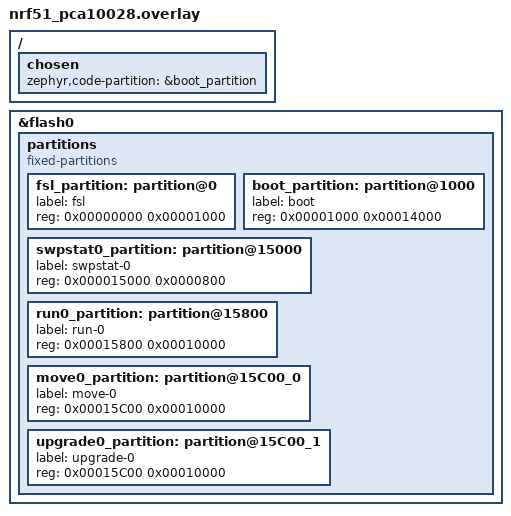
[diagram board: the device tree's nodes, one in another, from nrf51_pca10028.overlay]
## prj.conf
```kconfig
#CONFIG_HAS_FLASH_LOAD_OFFSET=y
CONFIG_USE_DT_CODE_PARTITION=y
CONFIG_TEXT_SECTION_OFFSET=0x200
CONFIG_ZB_EIGHT=y
CONFIG_ZB_EIGHT_DFU_BLOCK_BUF_SIZE=512
CONFIG_ZB_EIGHT_FSL_SUPPORT=y

CONFIG_ARM_MPU=n

CONFIG_MAIN_STACK_SIZE=320
CONFIG_IDLE_STACK_SIZE=128

CONFIG_LOG=n
CONFIG_CONSOLE=n
CONFIG_EARLY_CONSOLE=n
CONFIG_UART_CONSOLE=n
CONFIG_STDOUT_CONSOLE=n
CONFIG_PRINTK=n
CONFIG_SERIAL=n
CONFIG_GPIO=n
CONFIG_I2C=n
CONFIG_WATCHDOG=n
CONFIG_PINMUX=n
CONFIG_SPI=n
CONFIG_SYS_POWER_MANAGEMENT=n

#CONFIG_BT=y
#CONFIG_BT_SMP=n
#CONFIG_BT_PERIPHERAL=y
#CONFIG_BT_GATT_CACHING=n
#CONFIG_BT_DEBUG_LOG=n
#CONFIG_BT_GATT_DIS=n
#CONFIG_BT_GATT_DIS_PNP=n
#CONFIG_BT_DEVICE_NAME="Zephyr"
#CONFIG_BT_DEVICE_APPEARANCE=833

CONFIG_BT=y
CONFIG_BT_SMP=n
CONFIG_BT_PERIPHERAL=y
CONFIG_BT_GATT_CACHING=n
CONFIG_BT_CTLR_PRIVACY=n
CONFIG_BT_PHY_UPDATE=n
CONFIG_BT_DATA_LEN_UPDATE=n
#CONFIG_BT_ASSERT=n
CONFIG_BT_CTLR_LE_ENC=n
CONFIG_BT_CTLR_CONN_PARAM_REQ=n
CONFIG_BT_CTLR_EXT_REJ_IND=n
CONFIG_BT_CTLR_SLAVE_FEAT_REQ=n
CONFIG_BT_CTLR_MIN_USED_CHAN=n
CONFIG_BT_CTLR_CHAN_SEL_2=n
CONFIG_BT_CTLR_ADV_EXT=n
CONFIG_BT_CTLR_DTM_HCI=n
CONFIG_BT_CTLR_ADVANCED_FEATURES=n
```

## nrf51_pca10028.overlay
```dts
/*
 * Copyright (c) 2019 Laczen
 *
 * SPDX-License-Identifier: Apache-2.0
 */

/delete-node/ &boot_partition;
/delete-node/ &scratch_partition;
/delete-node/ &slot0_partition;
/delete-node/ &slot1_partition;
/delete-node/ &storage_partition;
/ {
	chosen {
		zephyr,code-partition = &boot_partition;
	};
};

&flash0 {
	/*
	 * For more information, see:
	 * http://docs.zephyrproject.org/latest/guides/dts/index.html#flash-partitions
	 */
	partitions {
		compatible = "fixed-partitions";
		#address-cells = <1>;
		#size-cells = <1>;

		fsl_partition: partition@0 {
			label = "fsl";
			reg = <0x00000000 0x00001000>;
		};
		boot_partition: partition@1000 {
			label = "boot";
			reg = <0x00001000 0x00014000>;
		};
		swpstat0_partition: partition@15000 {
			label = "swpstat-0";
			reg = <0x000015000 0x0000800>;
		};
		run0_partition: partition@15800 {
			label = "run-0";
			reg = <0x00015800 0x00010000>;
		};
		move0_partition: partition@15C00_0 {
			label = "move-0";
			reg = <0x00015C00 0x00010000>;
		};
		upgrade0_partition: partition@15C00_1 {
			label = "upgrade-0";
			reg = <0x00015C00 0x00010000>;
		};
	};
};
```

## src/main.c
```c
/* main.c - Application main entry point */

/*
 * Copyright (c) 2015-2016 Intel Corporation
 *
 * SPDX-License-Identifier: Apache-2.0
 */

#include <zephyr.h>

#include <bluetooth/gatt.h>

#include <zepboot/zb_fsl.h>
#include <zepboot/zb_dfu.h>
#include "nrf_dfu.h"


#include <logging/log.h>
LOG_MODULE_REGISTER(main);

struct bt_conn *default_conn;

static const struct bt_data ad[] = {
	BT_DATA_BYTES(BT_DATA_FLAGS, (BT_LE_AD_GENERAL | BT_LE_AD_NO_BREDR)),
	BT_DATA_BYTES(BT_DATA_UUID16_ALL, 0x0d, 0x18, 0x0f, 0x18, 0x05, 0x18),
};

static void connected(struct bt_conn *conn, u8_t err)
{
	if (err) {
		LOG_DBG("Connection failed (err 0x%02x)", err);
	} else {
		default_conn = bt_conn_ref(conn);
		LOG_INF("Connected");
	}
}

static void disconnected(struct bt_conn *conn, u8_t reason)
{
	LOG_INF("Disconnected (reason 0x%02x)", reason);

	if (default_conn) {
		bt_conn_unref(default_conn);
		default_conn = NULL;
	}
}

static struct bt_conn_cb conn_callbacks = {
	.connected = connected,
	.disconnected = disconnected,
};

static void bt_ready(int err)
{
	if (err) {
		LOG_DBG("Bluetooth init failed (err %d)", err);
		return;
	}

	LOG_INF("Bluetooth initialized");

	err = bt_le_adv_start(BT_LE_ADV_CONN_NAME, ad, ARRAY_SIZE(ad), NULL, 0);
	if (err) {
		LOG_DBG("Advertising failed to start (err %d)", err);
		return;
	}

	LOG_INF("Advertising successfully started");
}

static void reset_to_app(void)
{
	u8_t sm_idx;
	struct zb_fsl_ctx ctxb;

	zb_dfu_receive_flush(&sm_idx);
	LOG_INF("Receive finished, restarting to bootloader");
	/* Restart the bootloader */
	ctxb.addr = DT_FLASH_AREA_BOOT_OFFSET;
	ctxb.fl_dev = device_get_binding(DT_FLASH_AREA_BOOT_DEV);
	zb_fsl_verify(&ctxb);
	zb_fsl_boot(&ctxb);


}

struct nrf_dfu_cb dfu_callbacks = {
	.receive = &zb_dfu_receive,
	.reset_to_app = &reset_to_app,

};

static void dfu_init(void)
{
	nrf_dfu_init(&dfu_callbacks, 0U, 0U);
}

void main(void)
{
	int err;

	err = bt_enable(bt_ready);
	if (err) {
		LOG_DBG("Bluetooth init failed (err %d)", err);
		return;
	}

	bt_conn_cb_register(&conn_callbacks);
	dfu_init();
	LOG_INF("Welcome to ZEPBOOT bledfu uploader\n");

	while (1) {
		k_sleep(MSEC_PER_SEC);
	}
}
```

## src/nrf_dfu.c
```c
/** @file
 *  @brief NRF BLE DFU Service (Legacy)
 */

/*
 * Copyright (c) 2019 Linaro Limited
 *
 * SPDX-License-Identifier: Apache-2.0
 */

#include <zephyr.h>

#include <zephyr/types.h>
#include <misc/byteorder.h>

#include <bluetooth/bluetooth.h>
#include <bluetooth/conn.h>
#include <bluetooth/uuid.h>
#include <bluetooth/gatt.h>

#include <logging/log.h>
LOG_MODULE_REGISTER(nrf_dfu);

#include "nrf_dfu.h"

/* References:
 * https://infocenter.nordicsemi.com/topic/com.nordic.infocenter.sdk51.v10.0.0/bledfu_transport_bleservice.html
 * https://developer.nordicsemi.com/nRF51_SDK/nRF51_SDK_v5.x.x/doc/5.2.0/html/a00029.html
 */

#define DFU_OP_RFU		0
#define DFU_OP_START		1
#define DFU_OP_INIT		2
#define DFU_OP_RECV_IMG		3
#define DFU_OP_VALIDATE_IMG	4
#define DFU_OP_ACTIVATE_IMG	5
#define DFU_OP_RESET_SYS	6
#define DFU_OP_IMG_SIZE		7
#define DFU_OP_PKT_NOTIF_REQ	8
#define DFU_OP_RSP_CODE		16
#define DFU_OP_PKT_NOTIF	17

enum {
	RSP_RFU,
	RSP_SUCCESS,
	RSP_INVSTATE,
	RSP_NOTSUP,
	RSP_DATA_SIZE,
	RSP_CRC_ERROR,
	RSP_OP_FAILED
};

enum {
	DFU_STATE_NONE,
	DFU_STATE_BOOTLOADER,
	DFU_STATE_WAIT_START_PKT,
	DFU_STATE_STARTED,
	DFU_STATE_WAIT_INIT_PKT, /* Optional */
	DFU_STATE_RECV,
	DFU_STATE_RECV_DONE,
	DFU_STATE_VALIDATE,
};

struct dfu_start_data {
	u32_t softdevice_len;
	u32_t bootloader_len;
	u32_t application_len;
} __attribute__((packed));

struct dfu_init_data {
	u16_t device_type;
	u16_t device_revision;
	u32_t application_version;
	u16_t softdevice_id_count;
	u16_t softdevice_id[0];
} __attribute__((packed));

static struct bt_uuid_128 nrf_dfu_uuid = BT_UUID_INIT_128(
	0x23, 0xD1, 0xBC, 0xEA, 0x5F, 0x78, 0x23, 0x15,
	0xDE, 0xEF, 0x12, 0x12, 0x30, 0x15, 0x00, 0x00
);

static struct bt_uuid_128 nrf_dfu_control = BT_UUID_INIT_128(
	0x23, 0xD1, 0xBC, 0xEA, 0x5F, 0x78, 0x23, 0x15,
	0xDE, 0xEF, 0x12, 0x12, 0x31, 0x15, 0x00, 0x00
);

static struct bt_uuid_128 nrf_dfu_packet = BT_UUID_INIT_128(
	0x23, 0xD1, 0xBC, 0xEA, 0x5F, 0x78, 0x23, 0x15,
	0xDE, 0xEF, 0x12, 0x12, 0x32, 0x15, 0x00, 0x00
);

static struct bt_uuid_128 nrf_dfu_version = BT_UUID_INIT_128(
	0x23, 0xD1, 0xBC, 0xEA, 0x5F, 0x78, 0x23, 0x15,
	0xDE, 0xEF, 0x12, 0x12, 0x34, 0x15, 0x00, 0x00
);

static int state = DFU_STATE_NONE;
const struct bt_gatt_service_static nrf_dfu_svc;
static unsigned int exp_size, img_offset;
static u16_t device_type, device_revision;
static u16_t pkt_notif, pkt_count;
static u32_t crc16 = -1;
static struct nrf_dfu_cb *cb;

static void reset_state(struct bt_conn *conn)
{
	state = DFU_STATE_NONE;
	if (conn) {
		bt_conn_disconnect(conn, 0);
	}
}

static ssize_t write_control(struct bt_conn *conn,
			     const struct bt_gatt_attr *attr,
			     const void *buf, u16_t len, u16_t offset,
			     u8_t flags)
{
	u8_t opcode = ((u8_t *)buf)[0];
	u8_t rsp[3];

	/* prepare notification response */
	rsp[0] = DFU_OP_RSP_CODE;
	rsp[1] = opcode;
	rsp[2] = RSP_INVSTATE;

	switch (opcode) {
	case DFU_OP_START:
	{
		int err = 0;

		if (len != 2) {
			rsp[2] = RSP_OP_FAILED;
			bt_gatt_notify(conn, attr, &rsp, sizeof(rsp));
			break;
		}

		if (cb && cb->start) {
			err = cb->start(((u8_t *)buf)[1]);
		}

		if (state != DFU_STATE_BOOTLOADER
		    && cb && cb->reset_to_boot && !err) {
			/* Switch to bootloader mode */
			bt_conn_disconnect(conn, 0);
			state = DFU_STATE_BOOTLOADER;
			cb->reset_to_boot();
			break;
		}

		if (err) {
			rsp[2] = RSP_OP_FAILED;
			bt_gatt_notify(conn, attr, &rsp, sizeof(rsp));
			reset_state(conn);
		} else {
			pkt_notif = pkt_count = exp_size = img_offset = 0;
			state = DFU_STATE_WAIT_START_PKT;
		}

		break;
	}
	case DFU_OP_INIT:
	{
		if (state != DFU_STATE_STARTED) {
			bt_gatt_notify(conn, attr, &rsp, sizeof(rsp));
			reset_state(conn);
		} else {
			state = DFU_STATE_WAIT_INIT_PKT;
		}

		break;
	}
	case DFU_OP_RECV_IMG:
	{
		if (state != DFU_STATE_STARTED) {
			bt_gatt_notify(conn, attr, &rsp, sizeof(rsp));
			reset_state(conn);
		} else {
			state = DFU_STATE_RECV;
		}

		break;
	}
	case DFU_OP_VALIDATE_IMG:
	{
		if (state != DFU_STATE_RECV_DONE) {
			reset_state(conn);
		} else if (cb && cb->validate && cb->validate(crc16)) {
			rsp[2] = RSP_CRC_ERROR;
		} else {
			state = DFU_STATE_VALIDATE;
			rsp[2] = RSP_SUCCESS;
		}

		bt_gatt_notify(conn, attr, &rsp, sizeof(rsp));

		if (rsp[2] != RSP_SUCCESS) {
			reset_state(conn);
		}

		break;
	}
	case DFU_OP_ACTIVATE_IMG:
	{
		if (state != DFU_STATE_VALIDATE) {
			bt_gatt_notify(conn, attr, &rsp, sizeof(rsp));
			reset_state(conn);
		} else {
			reset_state(conn);

			if (cb && cb->reset_to_app) {
				/* Boot to app */
				cb->reset_to_app();
			}
		}
		break;
	}
	case DFU_OP_PKT_NOTIF_REQ:
	{
		/* pkt notification request */
		if (len != 3) {
			break;
		}

		pkt_notif = sys_le16_to_cpu(*(u16_t *)((u8_t *)buf + 1));

		break;
	}
	default: /* Unknown OPCODE */
		bt_gatt_notify(conn, attr, &rsp, sizeof(rsp));
	}

	return len;
}

static ssize_t write_packet(struct bt_conn *conn,
			    const struct bt_gatt_attr *attr,
			    const void *buf, u16_t len, u16_t offset,
			    u8_t flags)
{
	switch (state) {
	case DFU_STATE_WAIT_START_PKT:
	{
		u8_t rsp[] = {DFU_OP_RSP_CODE, DFU_OP_START, RSP_SUCCESS};
		const struct dfu_start_data *data = buf;

		if (len != sizeof(struct dfu_start_data)) {
			rsp[2] = RSP_OP_FAILED;
		} else {
			state = DFU_STATE_STARTED;
		}

		/* Only support Application update */
		exp_size = sys_le32_to_cpu(data->application_len);
		img_offset = 0;

		bt_gatt_notify(conn,  &nrf_dfu_svc.attrs[1], &rsp, sizeof(rsp));

		if (rsp[2] != RSP_SUCCESS) {
			reset_state(conn);
		}

		break;
	}
	case DFU_STATE_WAIT_INIT_PKT:
	{
		u8_t rsp[] = {DFU_OP_RSP_CODE, DFU_OP_INIT, RSP_SUCCESS};
		const struct dfu_init_data *init = buf;

		if (len < sizeof(*init) ||
		    len < (sizeof(*init) + init->softdevice_id_count)) {
			rsp[2] = RSP_OP_FAILED;
		} else {
			/* Go back to started state */
			state = DFU_STATE_STARTED;
		}

		/* Check device_type if any */
		if ((device_type != 0) && (device_type != init->device_type)) {
			rsp[2] = RSP_OP_FAILED;
		}

		/* Check device_revision if any */
		if ((device_revision != 0) &&
		    (device_revision != init->device_revision)) {
			rsp[2] = RSP_OP_FAILED;
		}

		/* do not care about softDevice, CRC1-16-CCIT is last field */
		crc16 = sys_le16_to_cpu(init->softdevice_id[init->softdevice_id_count]);

		bt_gatt_notify(conn,  &nrf_dfu_svc.attrs[1], &rsp, sizeof(rsp));

		if (rsp[2] != RSP_SUCCESS) {
			reset_state(conn);
		}

		break;
	}
	case DFU_STATE_RECV:
	{
		int err = 0;

		if (cb && cb->receive) {
			err = cb->receive(img_offset, buf, len);
		}

		exp_size -= len;
		img_offset += len;
		pkt_count++;

		if (pkt_notif && !(pkt_count % pkt_notif)) {
			u8_t rsp[] = { DFU_OP_PKT_NOTIF,
				       0x00, 0x00, 0x00, 0x00 };
			u32_t *bytes = (u32_t *)&rsp[2];

			*bytes = sys_cpu_to_le32(img_offset);

			/* Report Received Image Size */
			bt_gatt_notify(conn,  &nrf_dfu_svc.attrs[1], &rsp,
				       sizeof(rsp));
		}

		if (exp_size == 0 || err) {
			u8_t rsp[] = { DFU_OP_RSP_CODE, DFU_OP_RECV_IMG,
				       err ? RSP_OP_FAILED : RSP_SUCCESS };

			state = DFU_STATE_RECV_DONE;

			bt_gatt_notify(conn,  &nrf_dfu_svc.attrs[1], &rsp,
				       sizeof(rsp));

			if (rsp[2] != RSP_SUCCESS) {
				reset_state(conn);
			}
		}

		break;
	}
	default:
		return -EINVAL;
	}

	return len;
}

static ssize_t read_version(struct bt_conn *conn,
			    const struct bt_gatt_attr *attr,
			    void *buf, u16_t len, u16_t offset)
{
	u16_t version;
	ssize_t tmp;

	if (cb && cb->reset_to_boot && state != DFU_STATE_BOOTLOADER) {
		version = 0x0001; /* 0.1 (app mode) */
	} else {
		version = 0x0004; /* 0.4 (bootloader mode) */
	}

	LOG_INF("read_version [%d]", version);
	tmp = bt_gatt_attr_read(conn, attr, buf, len, offset, &version,
				 sizeof(version));
	LOG_INF("read_version [%d]", version);
	return tmp;

}

static void nrf_dfu_ccc_cfg_changed(const struct bt_gatt_attr *attr,
				    u16_t value)
{
	/* TODO: Handle value */
}

BT_GATT_SERVICE_DEFINE(nrf_dfu_svc,
	BT_GATT_PRIMARY_SERVICE(&nrf_dfu_uuid),
	BT_GATT_CHARACTERISTIC(&nrf_dfu_control.uuid,
			       BT_GATT_CHRC_WRITE | BT_GATT_CHRC_NOTIFY,
			       BT_GATT_PERM_WRITE,
			       NULL, write_control, NULL),
	BT_GATT_CCC(nrf_dfu_ccc_cfg_changed,
		BT_GATT_PERM_READ | BT_GATT_PERM_WRITE),
	BT_GATT_CHARACTERISTIC(&nrf_dfu_packet.uuid,
			       BT_GATT_CHRC_WRITE_WITHOUT_RESP,
			       BT_GATT_PERM_WRITE,
			       NULL, write_packet, NULL),
	BT_GATT_CHARACTERISTIC(&nrf_dfu_version.uuid,
			       BT_GATT_CHRC_READ,
			       BT_GATT_PERM_READ,
			       read_version, NULL, NULL),
);

void nrf_dfu_init(struct nrf_dfu_cb *callbacks, u16_t type, u16_t revision)
{
	cb = callbacks;
	device_type = type;
	device_revision = revision;
}
```

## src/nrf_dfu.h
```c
/** @file
 *  @brief NRF BLE DFU Service (Legacy)
 */

/*
 * Copyright (c) 2019 Linaro Limited
 *
 * SPDX-License-Identifier: Apache-2.0
 */
#ifdef __cplusplus
extern "C" {
#endif

/* DFU image type */
enum dfu_image_type {
	DFU_IMG_TYPE_NONE,
	DFU_IMG_TYPE_SOFT,
	DFU_IMG_TYPE_BOOT,
	DFU_IMG_TYPE_SOFTBOOT,
	DFU_IMG_TYPE_APP
};

/** @brief NRF DFU callbacks structure. */
struct nrf_dfu_cb {
	/** Attribute start callback (optional)
	 *
	 *  @param img_type   The image type to update
	 *
	 *  @return 0 on success, -errno code on error
	 */
	int (*start)(enum dfu_image_type img_type);

	/** Attribute receive callback (optional)
	 *
	 *  @param offset   image offset to update/write
	 *  @param data     pointer to img data chunk
	 *  @param len      img data chunk size
	 *
	 *  @return 0 on success, -errno code on error
	 */
	int (*receive)(u32_t offset, const u8_t *data, size_t len);

	/** Attribute validate callback (optional)
	 *
	 *  @param crc   expected updated image CRC16
	 *
	 *  @return 0 on success, -errno code on error
	 */
	int (*validate)(u16_t crc);

	/** Attribute reset_to_app callback (optional)
	 *
	 * Reset system to updated image.
	 */
	void (*reset_to_app)(void);

	/** Attribute reset_to_boot callback (optional)
	 *
	 * Reset system to bootloader mode for update.
	 * Can be NULL if already in bootloader mode.
	 */
	void (*reset_to_boot)(void);
};

/** @brief Initialize NRF DFU service.
 *
 *  Send an indication of attribute value change.
 *  Note: This function should only be called if CCC is declared with
 *  BT_GATT_CCC otherwise it cannot find a valid peer configuration.
 *
 *  Note: This procedure is asynchronous therefore the parameters need to
 *  remains valid while it is active.
 *
 *  @param cb Pointer to callbacks structure.
 *  @param device_type Device type ID to match for sw update, 0 if none.
 *  @param device_revision Device revision ID to match for sw update, 0 if none.
 */

void nrf_dfu_init(struct nrf_dfu_cb *cb, u16_t device_type,
		  u16_t device_revision);

#ifdef __cplusplus
}
#endif
```
